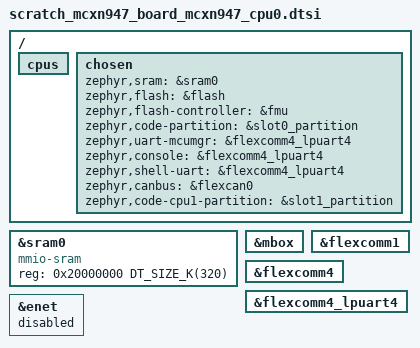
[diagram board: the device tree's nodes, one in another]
/*
 * Copyright 2024 NXP
 *
 * SPDX-License-Identifier: Apache-2.0
 */

/* Common dts file to enable supported features for CPU 0.
 * This file is included by both the default variant
 * which is run from internal flash and the QSPI variant.
 */
/dts-v1/;

#include <nxp/nxp_mcxn94x.dtsi>
#include "scratch_mcxn947_board.dtsi"

/ {
	cpus {
		/delete-node/ cpu@1;
	};

	chosen {
		zephyr,sram = &sram0;
		zephyr,flash = &flash;
		zephyr,flash-controller = &fmu;
		zephyr,code-partition = &slot0_partition;
		zephyr,uart-mcumgr = &flexcomm4_lpuart4;
		zephyr,console = &flexcomm4_lpuart4;
		zephyr,shell-uart = &flexcomm4_lpuart4;
		zephyr,canbus = &flexcan0;
		zephyr,code-cpu1-partition = &slot1_partition;
	};
};
/*
 * Default for this board is to allocate SRAM0-5 to cpu0 but the
 * application can have an application specific device tree to
 * allocate the SRAM0-7 differently.
 *
 * For example, SRAM0-6 could be allocated to cpu0 with only SRAM7
 * for cpu1. This would require the value of sram0 to have a DT_SIZE_K
 * of 384. You would have to make updates to cpu1 sram settings as well.
 */

&sram0 {
	compatible = "mmio-sram";
	reg = <0x20000000 DT_SIZE_K(320)>;
};

&mbox {
	status = "okay";
};

&flexcomm1 {
	status = "okay";
};

/*
 *LPFLEXCOMM supports UART and I2C on the same instance, enable this for
 * LFLEXCOMM2
 */

 &flexcomm4 {
	status = "okay";
};

&flexcomm4_lpuart4 {
	status = "okay";
};

&enet {
    status = "disabled";
};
